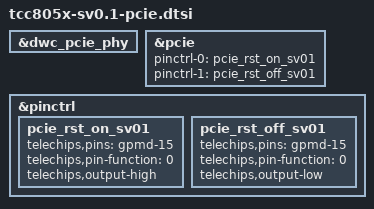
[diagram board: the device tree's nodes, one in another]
// SPDX-License-Identifier: (GPL-2.0-or-later OR MIT)
/*
 * Copyright (C) 2023 Telechips Inc.
 */

&dwc_pcie_phy {
	status = "okay";
};

&pcie {
	pinctrl-0 = <&pcie_rst_on_sv01>;
	pinctrl-1 = <&pcie_rst_off_sv01>;
	status = "okay";
};

&pinctrl {
	pcie_rst_on_sv01: pcie_rst_on_sv01 {
		telechips,pins = "gpmd-15";
		telechips,pin-function = <0>;
		telechips,output-high;
	};

	pcie_rst_off_sv01: pcie_rst_off_sv01 {
		telechips,pins = "gpmd-15";
		telechips,pin-function = <0>;
		telechips,output-low;
	};
};
